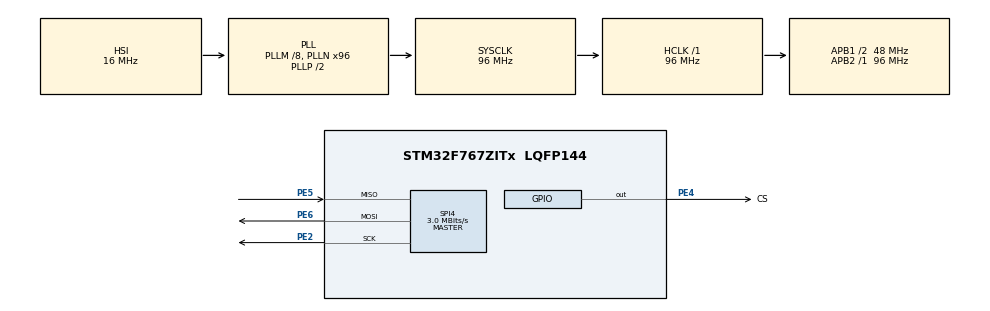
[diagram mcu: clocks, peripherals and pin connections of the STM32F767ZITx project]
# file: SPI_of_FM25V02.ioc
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Mcu.Family=STM32F7
Mcu.Name=STM32F767ZITx
Mcu.Package=LQFP144
NVIC.PriorityGroup=NVIC_PRIORITYGROUP_4
PA13.Mode=Serial_Wire
PA13.Signal=SYS_JTMS-SWDIO
PA14.Mode=Serial_Wire
PA14.Signal=SYS_JTCK-SWCLK
PE2.Mode=Full_Duplex_Master
PE2.Signal=SPI4_SCK
PE4.GPIO_Label=CS
PE4.GPIO_ModeDefaultOutputPP=GPIO_MODE_OUTPUT_PP
PE4.GPIO_PuPd=GPIO_NOPULL
PE4.GPIO_Speed=GPIO_SPEED_FREQ_LOW
PE4.PinState=GPIO_PIN_SET
PE4.Signal=GPIO_Output
PE5.Mode=Full_Duplex_Master
PE5.Signal=SPI4_MISO
PE6.Mode=Full_Duplex_Master
PE6.Signal=SPI4_MOSI
PH0/OSC_IN.Mode=HSE-External-Oscillator
PH0/OSC_IN.Signal=RCC_OSC_IN
PH1/OSC_OUT.Mode=HSE-External-Oscillator
PH1/OSC_OUT.Signal=RCC_OSC_OUT
ProjectManager.HeapSize=0x200
ProjectManager.StackSize=0x400
ProjectManager.TargetToolchain=TrueSTUDIO
RCC.48MHZClocksFreq_Value=24000000
RCC.AHBFreq_Value=96000000
RCC.APB1CLKDivider=RCC_HCLK_DIV2
RCC.APB1Freq_Value=48000000
RCC.APB1TimFreq_Value=96000000
RCC.APB2Freq_Value=96000000
RCC.APB2TimFreq_Value=96000000
RCC.CortexFreq_Value=96000000
RCC.HCLKFreq_Value=96000000
RCC.HSE_VALUE=8000000
RCC.HSI_VALUE=16000000
RCC.LSE_VALUE=32768
RCC.PLLM=8
RCC.PLLMUL=RCC_PLL_MUL9
RCC.PLLN=96
RCC.PLLQ=4
RCC.PRESCALERUSB=RCC_USBCLKSOURCE_PLL_DIV1_5
RCC.SYSCLKFreq_VALUE=96000000
RCC.SYSCLKSource=RCC_SYSCLKSOURCE_PLLCLK
RCC.SYSCLKSourceVirtual=RCC_SYSCLKSOURCE_PLLCLK
RCC.USBFreq_Value=48000000
RCC.VCOOutputFreq_Value=192000000
SPI4.BaudRatePrescaler=SPI_BAUDRATEPRESCALER_32
SPI4.CalculateBaudRate=3.0 MBits/s
SPI4.DataSize=SPI_DATASIZE_8BIT
SPI4.Direction=SPI_DIRECTION_2LINES
SPI4.Mode=SPI_MODE_MASTER
SPI4.VirtualType=VM_MASTER
board=NUCLEO-F767ZI

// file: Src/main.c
/* USER CODE BEGIN Header */
/**
  ******************************************************************************
  * @file           : main.c
  * @brief          : Main program body
  ******************************************************************************
  * @attention
  *
  * <h2><center>&copy; Copyright (c) 2019 STMicroelectronics.
  * All rights reserved.</center></h2>
  *
  * This software component is licensed by ST under BSD 3-Clause license,
  * the "License"; You may not use this file except in compliance with the
  * License. You may obtain a copy of the License at:
  *                        opensource.org/licenses/BSD-3-Clause
  *
  ******************************************************************************
  */
/* USER CODE END Header */

#include "main.h"

SPI_HandleTypeDef hspi4;

void SystemClock_Config(void);
static void MX_GPIO_Init(void);
static void MX_SPI4_Init(void);

/* USER CODE BEGIN 0 */
uint8_t spiTX[3],spiRX[32];
/* USER CODE END 0 */

int main(void)
{

  /* MCU Configuration--------------------------------------------------------*/

  /* Reset of all peripherals, Initializes the Flash interface and the Systick. */
  HAL_Init();

  /* Configure the system clock */
  SystemClock_Config();

  /* Initialize all configured peripherals */
  MX_GPIO_Init();
  MX_SPI4_Init();
  /* USER CODE BEGIN 2 */

  HAL_GPIO_WritePin(CS_GPIO_Port, CS_Pin, GPIO_PIN_SET);
  HAL_Delay(10);

  //Read DATA
  // 1. put cs low -> Activation of spi devise
  HAL_GPIO_WritePin(CS_GPIO_Port, CS_Pin, GPIO_PIN_RESET);

  //2. Transmit register adress
  spiTX[0]=0x06;
  HAL_SPI_Transmit(&hspi4,spiTX,1,100);
  //HAL_SPI_Receive(&hspi4,spiRX,8,100);
  HAL_GPIO_WritePin(CS_GPIO_Port, CS_Pin, GPIO_PIN_SET);

//  //3. memory write
//  HAL_GPIO_WritePin(CS_GPIO_Port, CS_Pin, GPIO_PIN_RESET);
//
//  spiTX[0]=0x02;
//  spiTX[1]=0x20;
//  spiTX[2]=0x11;
//  HAL_SPI_Transmit(&hspi4,spiTX,3,100);
// // HAL_SPI_Receive(&hspi4,spiRX,4,100);
//
//  //4. bring CS high -> Deactivate
//  HAL_GPIO_WritePin(CS_GPIO_Port, CS_Pin, GPIO_PIN_SET);

  /* USER CODE END 2 */

  /* Infinite loop */
  while (1)
  {

    /* USER CODE BEGIN 3 */

	  //3. memory read
	   HAL_GPIO_WritePin(CS_GPIO_Port, CS_Pin, GPIO_PIN_RESET);

	   spiTX[0]=0x9F;
	   HAL_SPI_Transmit(&hspi4,spiTX,1,100);
	   HAL_SPI_Receive(&hspi4,spiRX,4,100);

	   //4. bring CS high -> Deactivate
	   HAL_GPIO_WritePin(CS_GPIO_Port, CS_Pin, GPIO_PIN_SET);
	   HAL_Delay(300);

  }
  /* USER CODE END 3 */
}

void SystemClock_Config(void)
{
  RCC_OscInitTypeDef RCC_OscInitStruct = {0};
  RCC_ClkInitTypeDef RCC_ClkInitStruct = {0};

  /** Configure the main internal regulator output voltage
  */
  __HAL_RCC_PWR_CLK_ENABLE();
  __HAL_PWR_VOLTAGESCALING_CONFIG(PWR_REGULATOR_VOLTAGE_SCALE3);
  /** Initializes the CPU, AHB and APB busses clocks
  */
  RCC_OscInitStruct.OscillatorType = RCC_OSCILLATORTYPE_HSI;
  RCC_OscInitStruct.HSIState = RCC_HSI_ON;
  RCC_OscInitStruct.HSICalibrationValue = RCC_HSICALIBRATION_DEFAULT;
  RCC_OscInitStruct.PLL.PLLState = RCC_PLL_ON;
  RCC_OscInitStruct.PLL.PLLSource = RCC_PLLSOURCE_HSI;
  RCC_OscInitStruct.PLL.PLLM = 8;
  RCC_OscInitStruct.PLL.PLLN = 96;
  RCC_OscInitStruct.PLL.PLLP = RCC_PLLP_DIV2;
  RCC_OscInitStruct.PLL.PLLQ = 4;
  if (HAL_RCC_OscConfig(&RCC_OscInitStruct) != HAL_OK)
  {
    Error_Handler();
  }
  /** Activate the Over-Drive mode
  */
  if (HAL_PWREx_EnableOverDrive() != HAL_OK)
  {
    Error_Handler();
  }
  /** Initializes the CPU, AHB and APB busses clocks
  */
  RCC_ClkInitStruct.ClockType = RCC_CLOCKTYPE_HCLK|RCC_CLOCKTYPE_SYSCLK
                              |RCC_CLOCKTYPE_PCLK1|RCC_CLOCKTYPE_PCLK2;
  RCC_ClkInitStruct.SYSCLKSource = RCC_SYSCLKSOURCE_PLLCLK;
  RCC_ClkInitStruct.AHBCLKDivider = RCC_SYSCLK_DIV1;
  RCC_ClkInitStruct.APB1CLKDivider = RCC_HCLK_DIV2;
  RCC_ClkInitStruct.APB2CLKDivider = RCC_HCLK_DIV1;

  if (HAL_RCC_ClockConfig(&RCC_ClkInitStruct, FLASH_LATENCY_3) != HAL_OK)
  {
    Error_Handler();
  }
}

static void MX_SPI4_Init(void)
{

  /* SPI4 parameter configuration*/
  hspi4.Instance = SPI4;
  hspi4.Init.Mode = SPI_MODE_MASTER;
  hspi4.Init.Direction = SPI_DIRECTION_2LINES;
  hspi4.Init.DataSize = SPI_DATASIZE_8BIT;
  hspi4.Init.CLKPolarity = SPI_POLARITY_LOW;
  hspi4.Init.CLKPhase = SPI_PHASE_1EDGE;
  hspi4.Init.NSS = SPI_NSS_SOFT;
  hspi4.Init.BaudRatePrescaler = SPI_BAUDRATEPRESCALER_32;
  hspi4.Init.FirstBit = SPI_FIRSTBIT_MSB;
  hspi4.Init.TIMode = SPI_TIMODE_DISABLE;
  hspi4.Init.CRCCalculation = SPI_CRCCALCULATION_DISABLE;
  hspi4.Init.CRCPolynomial = 7;
  hspi4.Init.CRCLength = SPI_CRC_LENGTH_DATASIZE;
  hspi4.Init.NSSPMode = SPI_NSS_PULSE_ENABLE;
  if (HAL_SPI_Init(&hspi4) != HAL_OK)
  {
    Error_Handler();
  }

}

static void MX_GPIO_Init(void)
{
  GPIO_InitTypeDef GPIO_InitStruct = {0};

  /* GPIO Ports Clock Enable */
  __HAL_RCC_GPIOE_CLK_ENABLE();
  __HAL_RCC_GPIOH_CLK_ENABLE();
  __HAL_RCC_GPIOA_CLK_ENABLE();

  /*Configure GPIO pin Output Level */
  HAL_GPIO_WritePin(CS_GPIO_Port, CS_Pin, GPIO_PIN_SET);

  /*Configure GPIO pin : CS_Pin */
  GPIO_InitStruct.Pin = CS_Pin;
  GPIO_InitStruct.Mode = GPIO_MODE_OUTPUT_PP;
  GPIO_InitStruct.Pull = GPIO_NOPULL;
  GPIO_InitStruct.Speed = GPIO_SPEED_FREQ_LOW;
  HAL_GPIO_Init(CS_GPIO_Port, &GPIO_InitStruct);

}

void Error_Handler(void)
{
}

/************************ (C) COPYRIGHT STMicroelectronics *****END OF FILE****/
